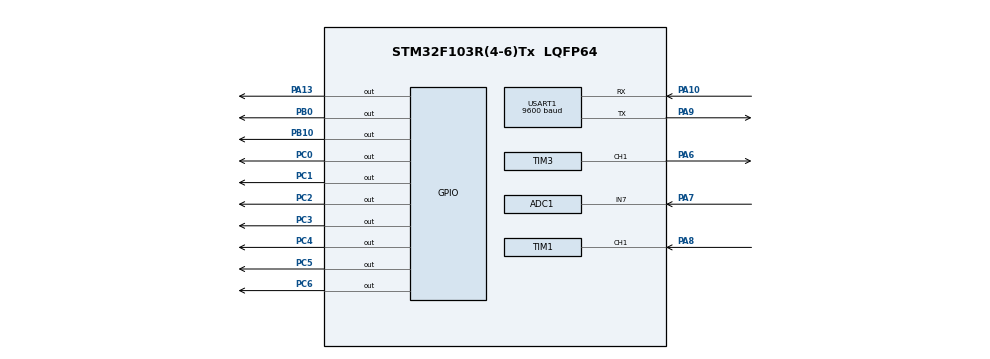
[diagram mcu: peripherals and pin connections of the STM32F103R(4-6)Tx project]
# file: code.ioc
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ADC1.Channel-2\#ChannelRegularConversion=ADC_CHANNEL_7
ADC1.NbrOfConversionFlag=1
ADC1.Rank-2\#ChannelRegularConversion=1
ADC1.SamplingTime-2\#ChannelRegularConversion=ADC_SAMPLETIME_1CYCLE_5
ADC1.master=1
FREERTOS.Tasks01=defaultTask,24,128,StartDefaultTask,Default,NULL,Dynamic,NULL,NULL
FREERTOS.configTOTAL_HEAP_SIZE=4096
Mcu.Family=STM32F1
Mcu.Name=STM32F103R(4-6)Tx
Mcu.Package=LQFP64
NVIC.ADC1_2_IRQn=true\:5\:0\:false\:false\:true\:true\:true\:true
NVIC.PriorityGroup=NVIC_PRIORITYGROUP_4
NVIC.TIM1_CC_IRQn=true\:5\:0\:false\:false\:true\:true\:true\:true
NVIC.TIM2_IRQn=true\:15\:0\:false\:false\:true\:false\:false\:true
NVIC.TimeBase=TIM2_IRQn
NVIC.TimeBaseIP=TIM2
NVIC.USART1_IRQn=true\:5\:0\:false\:false\:true\:true\:true\:true
PA10.Mode=Asynchronous
PA10.Signal=USART1_RX
PA13.GPIO_PuPd=GPIO_PULLUP
PA13.Signal=GPIO_Output
PA6.Signal=S_TIM3_CH1
PA7.Signal=ADCx_IN7
PA8.Signal=S_TIM1_CH1
PA9.Mode=Asynchronous
PA9.Signal=USART1_TX
PB0.GPIO_PuPd=GPIO_PULLUP
PB0.Signal=GPIO_Output
PB10.GPIO_PuPd=GPIO_PULLUP
PB10.Signal=GPIO_Output
PC0.GPIO_ModeDefaultOutputPP=GPIO_MODE_OUTPUT_PP
PC0.GPIO_PuPd=GPIO_PULLDOWN
PC0.GPIO_Speed=GPIO_SPEED_FREQ_LOW
PC0.PinState=GPIO_PIN_RESET
PC0.Signal=GPIO_Output
PC1.GPIO_ModeDefaultOutputPP=GPIO_MODE_OUTPUT_PP
PC1.GPIO_PuPd=GPIO_PULLDOWN
PC1.GPIO_Speed=GPIO_SPEED_FREQ_LOW
PC1.PinState=GPIO_PIN_RESET
PC1.Signal=GPIO_Output
PC2.GPIO_ModeDefaultOutputPP=GPIO_MODE_OUTPUT_PP
PC2.GPIO_PuPd=GPIO_PULLDOWN
PC2.GPIO_Speed=GPIO_SPEED_FREQ_LOW
PC2.PinState=GPIO_PIN_RESET
PC2.Signal=GPIO_Output
PC3.GPIO_ModeDefaultOutputPP=GPIO_MODE_OUTPUT_PP
PC3.GPIO_PuPd=GPIO_PULLDOWN
PC3.GPIO_Speed=GPIO_SPEED_FREQ_LOW
PC3.PinState=GPIO_PIN_RESET
PC3.Signal=GPIO_Output
PC4.GPIO_ModeDefaultOutputPP=GPIO_MODE_OUTPUT_PP
PC4.GPIO_PuPd=GPIO_PULLDOWN
PC4.GPIO_Speed=GPIO_SPEED_FREQ_LOW
PC4.PinState=GPIO_PIN_RESET
PC4.Signal=GPIO_Output
PC5.GPIO_ModeDefaultOutputPP=GPIO_MODE_OUTPUT_PP
PC5.GPIO_PuPd=GPIO_PULLDOWN
PC5.GPIO_Speed=GPIO_SPEED_FREQ_LOW
PC5.PinState=GPIO_PIN_RESET
PC5.Signal=GPIO_Output
PC6.GPIO_ModeDefaultOutputPP=GPIO_MODE_OUTPUT_PP
PC6.GPIO_PuPd=GPIO_PULLDOWN
PC6.GPIO_Speed=GPIO_SPEED_FREQ_LOW
PC6.PinState=GPIO_PIN_RESET
PC6.Signal=GPIO_Output
ProjectManager.HeapSize=0x200
ProjectManager.StackSize=0x400
ProjectManager.TargetToolchain=Makefile
RCC.APB1Freq_Value=8000000
RCC.APB2Freq_Value=8000000
SH.ADCx_IN7.0=ADC1_IN7,IN7
SH.S_TIM1_CH1.0=TIM1_CH1,Input_Capture1_from_TI1
SH.S_TIM3_CH1.0=TIM3_CH1,PWM Generation1 CH1
TIM1.Channel-Input_Capture1_from_TI1=TIM_CHANNEL_1
TIM1.Prescaler=7999
TIM3.Channel-PWM\ Generation1\ CH1=TIM_CHANNEL_1
TIM3.OCPolarity_1=TIM_OCPOLARITY_LOW
TIM3.Period=9
TIM3.Prescaler=7999
USART1.BaudRate=9600
USART1.VirtualMode=VM_ASYNC
VP_FREERTOS_VS_CMSIS_V2.Mode=CMSIS_V2
VP_SYS_VS_ND.Mode=No_Debug
VP_SYS_VS_tim2.Mode=TIM2
VP_TIM3_VS_ClockSourceINT.Mode=Internal
board=custom

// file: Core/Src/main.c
/* USER CODE BEGIN Header */
/**
 ******************************************************************************
 * @file           : main.c
 * @brief          : Main program body
 ******************************************************************************
 * @attention
 *
 * <h2><center>&copy; Copyright (c) 2022 STMicroelectronics.
 * All rights reserved.</center></h2>
 *
 * This software component is licensed by ST under Ultimate Liberty license
 * SLA0044, the "License"; You may not use this file except in compliance with
 * the License. You may obtain a copy of the License at:
 *                             www.st.com/SLA0044
 *
 ******************************************************************************
 */
/* USER CODE END Header */
#include "main.h"
#include "cmsis_os.h"
#include "adc.h"
#include "tim.h"
#include "usart.h"
#include "gpio.h"

/* USER CODE BEGIN Includes */
#include "homework.h"
/* USER CODE END Includes */

void SystemClock_Config(void);
void MX_FREERTOS_Init(void);

int main(void)
{

  /* MCU Configuration--------------------------------------------------------*/

  /* Reset of all peripherals, Initializes the Flash interface and the Systick. */
  HAL_Init();

  /* Configure the system clock */
  SystemClock_Config();

  /* Initialize all configured peripherals */
  MX_GPIO_Init();
  MX_USART1_UART_Init();
  MX_TIM3_Init();
  MX_ADC1_Init();
  MX_TIM1_Init();
  /* USER CODE BEGIN 2 */
  homeworkInit();
  /* USER CODE END 2 */

  /* Init scheduler */
  osKernelInitialize();  /* Call init function for freertos objects (in freertos.c) */
  MX_FREERTOS_Init();
  /* Start scheduler */
  osKernelStart();

  /* We should never get here as control is now taken by the scheduler */
  /* Infinite loop */
	while (1)
	{

	}
}

void SystemClock_Config(void)
{
  RCC_OscInitTypeDef RCC_OscInitStruct = {0};
  RCC_ClkInitTypeDef RCC_ClkInitStruct = {0};
  RCC_PeriphCLKInitTypeDef PeriphClkInit = {0};

  /** Initializes the RCC Oscillators according to the specified parameters
  * in the RCC_OscInitTypeDef structure.
  */
  RCC_OscInitStruct.OscillatorType = RCC_OSCILLATORTYPE_HSI;
  RCC_OscInitStruct.HSIState = RCC_HSI_ON;
  RCC_OscInitStruct.HSICalibrationValue = RCC_HSICALIBRATION_DEFAULT;
  RCC_OscInitStruct.PLL.PLLState = RCC_PLL_NONE;
  if (HAL_RCC_OscConfig(&RCC_OscInitStruct) != HAL_OK)
  {
    Error_Handler();
  }
  /** Initializes the CPU, AHB and APB buses clocks
  */
  RCC_ClkInitStruct.ClockType = RCC_CLOCKTYPE_HCLK|RCC_CLOCKTYPE_SYSCLK
                              |RCC_CLOCKTYPE_PCLK1|RCC_CLOCKTYPE_PCLK2;
  RCC_ClkInitStruct.SYSCLKSource = RCC_SYSCLKSOURCE_HSI;
  RCC_ClkInitStruct.AHBCLKDivider = RCC_SYSCLK_DIV1;
  RCC_ClkInitStruct.APB1CLKDivider = RCC_HCLK_DIV1;
  RCC_ClkInitStruct.APB2CLKDivider = RCC_HCLK_DIV1;

  if (HAL_RCC_ClockConfig(&RCC_ClkInitStruct, FLASH_LATENCY_0) != HAL_OK)
  {
    Error_Handler();
  }
  PeriphClkInit.PeriphClockSelection = RCC_PERIPHCLK_ADC;
  PeriphClkInit.AdcClockSelection = RCC_ADCPCLK2_DIV2;
  if (HAL_RCCEx_PeriphCLKConfig(&PeriphClkInit) != HAL_OK)
  {
    Error_Handler();
  }
}

/* USER CODE BEGIN 4 */
extern uint32_t overflow;
/* USER CODE END 4 */

void HAL_TIM_PeriodElapsedCallback(TIM_HandleTypeDef *htim)
{
  if (htim->Instance == TIM2) {
    HAL_IncTick();
  }
  /* USER CODE BEGIN Callback 1 */
  if(htim->Instance==htim1.Instance){
	  overflow++;
  }
  /* USER CODE END Callback 1 */
}

void Error_Handler(void)
{
	__disable_irq();
	while (1)
	{
	}
}

/************************ (C) COPYRIGHT STMicroelectronics *****END OF FILE****/
